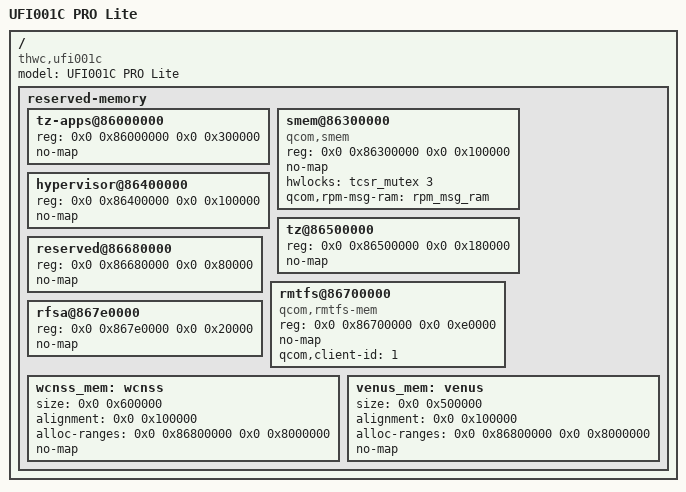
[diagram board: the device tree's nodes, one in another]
// SPDX-License-Identifier: GPL-2.0-only

/dts-v1/;

#include "msm8916-thwc-ufi001c-pro.dts"

/ {
	model = "UFI001C PRO Lite";
	compatible = "thwc,ufi001c", "qcom,msm8916";

	reserved-memory {
		#address-cells = <2>;
		#size-cells = <2>;
		ranges;

		tz-apps@86000000 {
			reg = <0x0 0x86000000 0x0 0x300000>;
			no-map;
		};

		smem@86300000 {
			compatible = "qcom,smem";
			reg = <0x0 0x86300000 0x0 0x100000>;
			no-map;

			hwlocks = <&tcsr_mutex 3>;
			qcom,rpm-msg-ram = <&rpm_msg_ram>;
		};

		hypervisor@86400000 {
			reg = <0x0 0x86400000 0x0 0x100000>;
			no-map;
		};

		tz@86500000 {
			reg = <0x0 0x86500000 0x0 0x180000>;
			no-map;
		};

		reserved@86680000 {
			reg = <0x0 0x86680000 0x0 0x80000>;
			no-map;
		};

		rmtfs@86700000 {
			compatible = "qcom,rmtfs-mem";
			reg = <0x0 0x86700000 0x0 0xe0000>;
			no-map;

			qcom,client-id = <1>;
		};

		rfsa@867e0000 {
			reg = <0x0 0x867e0000 0x0 0x20000>;
			no-map;
		};

		wcnss_mem: wcnss {
			size = <0x0 0x600000>;
			alignment = <0x0 0x100000>;
			alloc-ranges = <0x0 0x86800000 0x0 0x8000000>;
			no-map;
			status = "okay";
		};

		venus_mem: venus {
			size = <0x0 0x500000>;
			alignment = <0x0 0x100000>;
			alloc-ranges = <0x0 0x86800000 0x0 0x8000000>;
			no-map;
			status = "okay";
		};
	};
};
